AUTOSAR XML (schema 4.0)
package /Battery_EV_Components
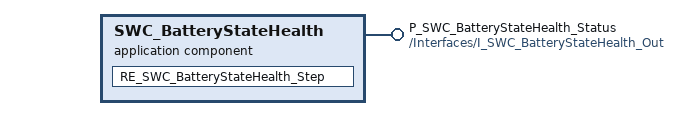
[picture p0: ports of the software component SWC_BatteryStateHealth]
  application sw component type SWC_BatteryStateHealth  # AUTOSAR Application SWC SWC_BatteryStateHealth for Battery EV Safety
    provide port P_SWC_BatteryStateHealth_Status: provided-interface=/Interfaces/I_SWC_BatteryStateHealth_Out
    behavior SWC_BatteryStateHealth_Behavior
      runnable RE_SWC_BatteryStateHealth_Step: symbol=SWC_BatteryStateHealth_Step
  sender receiver interface I_SWC_BatteryStateHealth_Out
    data DE_SWC_BatteryStateHealth_Health: type=/AUTOSAR/Platform/uint32
